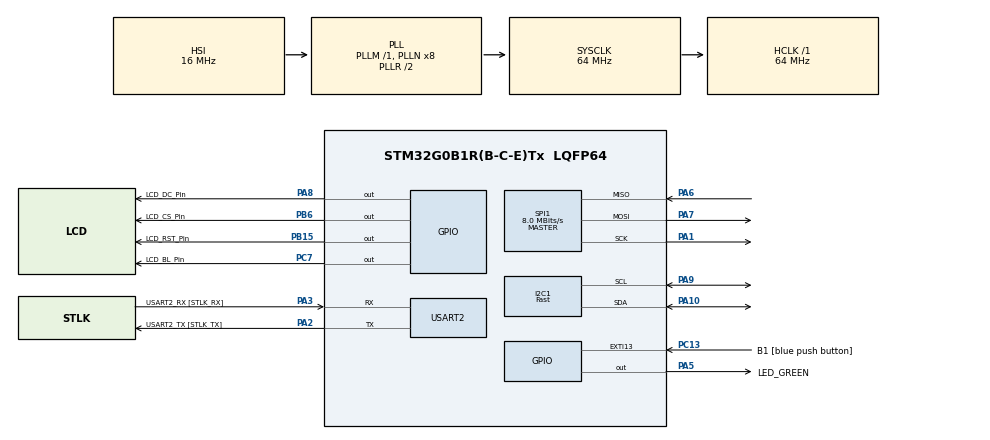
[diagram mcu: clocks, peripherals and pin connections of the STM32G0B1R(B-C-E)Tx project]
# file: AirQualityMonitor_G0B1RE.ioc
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I2C1.I2C_Speed_Mode=I2C_Fast
I2C1.Timing=0x00C12166
Mcu.Family=STM32G0
Mcu.Name=STM32G0B1R(B-C-E)Tx
Mcu.Package=LQFP64
PA1.Mode=Full_Duplex_Master
PA1.Signal=SPI1_SCK
PA10.Mode=I2C
PA10.Signal=I2C1_SDA
PA13.GPIO_Label=TMS
PA13.Mode=Serial_Wire
PA13.Signal=SYS_SWDIO
PA14-BOOT0.GPIO_Label=TCK
PA14-BOOT0.Mode=Serial_Wire
PA14-BOOT0.Signal=SYS_SWCLK
PA2.GPIO_Label=USART2_TX [STLK_TX]
PA2.Mode=Asynchronous
PA2.Signal=USART2_TX
PA3.GPIO_Label=USART2_RX [STLK_RX]
PA3.Mode=Asynchronous
PA3.Signal=USART2_RX
PA5.GPIO_Label=LED_GREEN
PA5.GPIO_Speed=GPIO_SPEED_FREQ_HIGH
PA5.Signal=GPIO_Output
PA6.Mode=Full_Duplex_Master
PA6.Signal=SPI1_MISO
PA7.Mode=Full_Duplex_Master
PA7.Signal=SPI1_MOSI
PA8.GPIO_Label=LCD_DC_Pin
PA8.GPIO_Speed=GPIO_SPEED_FREQ_VERY_HIGH
PA8.Signal=GPIO_Output
PA9.Mode=I2C
PA9.Signal=I2C1_SCL
PB15.GPIO_Label=LCD_RST_Pin
PB15.GPIO_Speed=GPIO_SPEED_FREQ_VERY_HIGH
PB15.Signal=GPIO_Output
PB6.GPIO_Label=LCD_CS_Pin
PB6.PinState=GPIO_PIN_RESET
PB6.Signal=GPIO_Output
PC13.GPIO_Label=B1 [blue push button]
PC13.Signal=GPXTI13
PC14-OSC32_IN\ (PC14).Mode=LSE-External-Oscillator
PC14-OSC32_IN\ (PC14).Signal=RCC_OSC32_IN
PC15-OSC32_OUT\ (PC15).Mode=LSE-External-Oscillator
PC15-OSC32_OUT\ (PC15).Signal=RCC_OSC32_OUT
PC7.GPIO_Label=LCD_BL_Pin
PC7.GPIO_PuPd=GPIO_NOPULL
PC7.GPIO_Speed=GPIO_SPEED_FREQ_VERY_HIGH
PC7.PinState=GPIO_PIN_SET
PC7.Signal=GPIO_Output
PF0-OSC_IN\ (PF0).GPIO_Label=MCO
PF0-OSC_IN\ (PF0).Mode=HSE-External-Oscillator
PF0-OSC_IN\ (PF0).Signal=RCC_OSC_IN
PF1-OSC_OUT\ (PF1).Mode=HSE-External-Oscillator
PF1-OSC_OUT\ (PF1).Signal=RCC_OSC_OUT
ProjectManager.HeapSize=0x200
ProjectManager.StackSize=0x400
ProjectManager.TargetToolchain=STM32CubeIDE
RCC.ADCFreq_Value=64000000
RCC.AHBFreq_Value=64000000
RCC.CortexFreq_Value=64000000
RCC.EXTERNAL_CLOCK_VALUE=12288000
RCC.HCLKFreq_Value=64000000
RCC.HSE_VALUE=8000000
RCC.HSI48_VALUE=48000000
RCC.HSI_VALUE=16000000
RCC.SYSCLKFreq_VALUE=64000000
RCC.SYSCLKSource=RCC_SYSCLKSOURCE_PLLCLK
RCC.USBFreq_Value=48000000
RCC.VCOOutputFreq_Value=128000000
SPI1.BaudRatePrescaler=SPI_BAUDRATEPRESCALER_8
SPI1.CalculateBaudRate=8.0 MBits/s
SPI1.DataSize=SPI_DATASIZE_8BIT
SPI1.Direction=SPI_DIRECTION_2LINES
SPI1.Mode=SPI_MODE_MASTER
SPI1.VirtualType=VM_MASTER
USART2.VirtualMode-Asynchronous=VM_ASYNC
VP_SYS_VS_DBSignals.Mode=DisableDeadBatterySignals
board=NUCLEO-G0B1RE

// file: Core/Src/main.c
/* USER CODE BEGIN Header */
/**
  ******************************************************************************
  * @file           : main.c
  * @brief          : Main program body
  ******************************************************************************
  * @attention
  *
  * Copyright (c) 2025 STMicroelectronics.
  * All rights reserved.
  *
  * This software is licensed under terms that can be found in the LICENSE file
  * in the root directory of this software component.
  * If no LICENSE file comes with this software, it is provided AS-IS.
  *
  ******************************************************************************
  */
/* USER CODE END Header */
#include "main.h"
#include "i2c.h"
#include "spi.h"
#include "usart.h"
#include "gpio.h"

/* USER CODE BEGIN Includes */
#include "bme69x.h" // Bosch driver header
#include "stdio.h"
#include "fonts.h"
#include "stdbool.h"
#include "st7789.h"

/* USER CODE END Includes */

/* USER CODE BEGIN PV */
// Declare SPI and I2C handles from CubeIDE generated code
extern SPI_HandleTypeDef hspi1;
extern I2C_HandleTypeDef hi2c1;

/* USER CODE END PV */

void SystemClock_Config(void);

int main(void)
{

  /* MCU Configuration--------------------------------------------------------*/

  /* Reset of all peripherals, Initializes the Flash interface and the Systick. */
  HAL_Init();

  /* Configure the system clock */
  SystemClock_Config();

  /* Initialize all configured peripherals */
  MX_GPIO_Init();
  MX_USART2_UART_Init();
  MX_I2C1_Init();
  MX_SPI1_Init();

  /* USER CODE BEGIN 2 */
  ST7789_Init(&hspi1); // Initialize the display

  ST7789_FillScreen(ST7789_BLUE);
    HAL_Delay(500);
    ST7789_WriteString(10, 10, "Hello, Gemini!", &Font16, ST7789_WHITE, ST7789_BLUE);
    ST7789_WriteString(10, 40, "STM32 NUCLEO-G0B1RE", &Font16, ST7789_YELLOW, ST7789_BLUE);
    ST7789_WriteString(10, 60, "Waveshare 1.69inch LCD", &Font16, ST7789_GREENYELLOW, ST7789_BLUE);
    ST7789_WriteString(10, 90, "Display Demo", &Font16, ST7789_CYAN, ST7789_BLUE);

  /* USER CODE END 2 */

  /* Infinite loop */
  while (1)
  {

	}
}

void SystemClock_Config(void)
{
  RCC_OscInitTypeDef RCC_OscInitStruct = {0};
  RCC_ClkInitTypeDef RCC_ClkInitStruct = {0};

  /** Configure the main internal regulator output voltage
  */
  HAL_PWREx_ControlVoltageScaling(PWR_REGULATOR_VOLTAGE_SCALE1);

  /** Initializes the RCC Oscillators according to the specified parameters
  * in the RCC_OscInitTypeDef structure.
  */
  RCC_OscInitStruct.OscillatorType = RCC_OSCILLATORTYPE_HSI;
  RCC_OscInitStruct.HSIState = RCC_HSI_ON;
  RCC_OscInitStruct.HSIDiv = RCC_HSI_DIV1;
  RCC_OscInitStruct.HSICalibrationValue = RCC_HSICALIBRATION_DEFAULT;
  RCC_OscInitStruct.PLL.PLLState = RCC_PLL_ON;
  RCC_OscInitStruct.PLL.PLLSource = RCC_PLLSOURCE_HSI;
  RCC_OscInitStruct.PLL.PLLM = RCC_PLLM_DIV1;
  RCC_OscInitStruct.PLL.PLLN = 8;
  RCC_OscInitStruct.PLL.PLLP = RCC_PLLP_DIV2;
  RCC_OscInitStruct.PLL.PLLQ = RCC_PLLQ_DIV2;
  RCC_OscInitStruct.PLL.PLLR = RCC_PLLR_DIV2;
  if (HAL_RCC_OscConfig(&RCC_OscInitStruct) != HAL_OK)
  {
    Error_Handler();
  }

  /** Initializes the CPU, AHB and APB buses clocks
  */
  RCC_ClkInitStruct.ClockType = RCC_CLOCKTYPE_HCLK|RCC_CLOCKTYPE_SYSCLK
                              |RCC_CLOCKTYPE_PCLK1;
  RCC_ClkInitStruct.SYSCLKSource = RCC_SYSCLKSOURCE_PLLCLK;
  RCC_ClkInitStruct.AHBCLKDivider = RCC_SYSCLK_DIV1;
  RCC_ClkInitStruct.APB1CLKDivider = RCC_HCLK_DIV1;

  if (HAL_RCC_ClockConfig(&RCC_ClkInitStruct, FLASH_LATENCY_2) != HAL_OK)
  {
    Error_Handler();
  }
}

void Error_Handler(void)
{
  __disable_irq();
  while (1)
  {
  }
}
